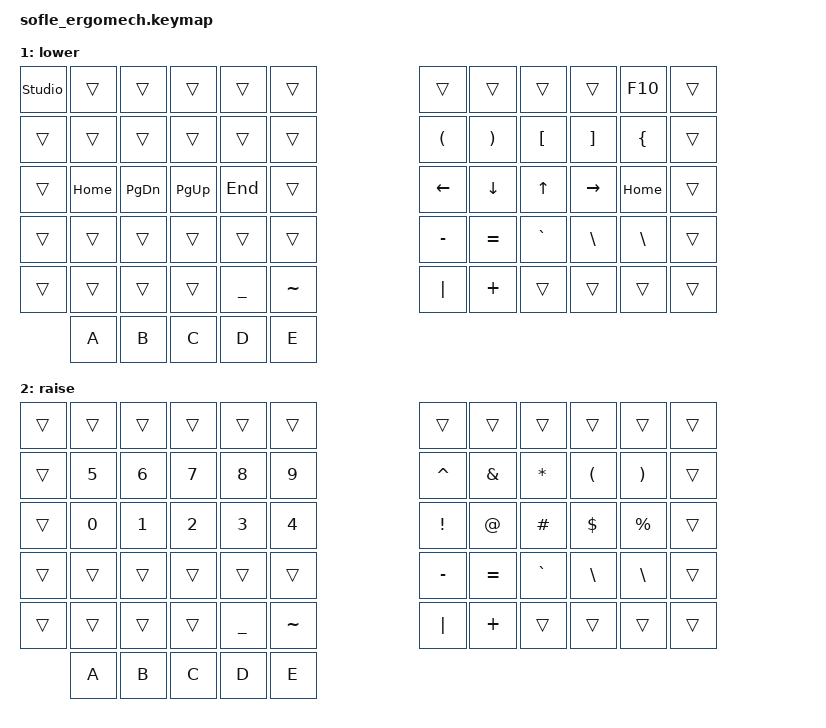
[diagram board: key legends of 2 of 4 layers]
/*
 * Copyright (c) 2020 The ZMK Contributors
 *
 * SPDX-License-Identifier: MIT
 */

#include <behaviors.dtsi>
#include <dt-bindings/zmk/bt.h>
#include <dt-bindings/zmk/ext_power.h>
#include <dt-bindings/zmk/keys.h>
#include <dt-bindings/zmk/rgb.h>

#define BASE 0
#define LOWER 1
#define RAISE 2
#define ADJUST 3

/ {
    behaviors {
        hml: home_row_mod_left {
            compatible = "zmk,behavior-hold-tap";
            #binding-cells = <2>;
            flavor = "tap-preferred";
            require-prior-idle-ms = <200>;
            tapping-term-ms = <175>;
            quick-tap-ms = <175>;
            bindings = <&kp>, <&kp>;
            hold-trigger-key-positions = <6 7 8 9 10 18 19 20 21 22 30 31 32 33 34 44 45 46 47 52 53>; // right hand
            hold-trigger-on-release;
        };
        hmr: home_row_mod_right {
            compatible = "zmk,behavior-hold-tap";
            #binding-cells = <2>;
            flavor = "tap-preferred";
            require-prior-idle-ms = <200>;
            tapping-term-ms = <280>;
            quick-tap-ms = <175>;
            bindings = <&kp>, <&kp>;
            hold-trigger-key-positions = <0 1 2 3 4 12 13 14 15 16 24 25 26 27 28 37 38 39 40 48 49>; // left hand
            hold-trigger-on-release;
        };
    };
    // Activate ADJUST layer by pressing raise and lower

    conditional_layers {
        compatible = "zmk,conditional-layers";

        adjust_layer {
            if-layers = <LOWER RAISE>;
            then-layer = <ADJUST>;
        };
    };

   key-positions {
       compatible = "zmk,key-positions";
       positions = <
            0  1  2  3  4  5     6  7  8  9 10 11
           12 13 14 15 16 17    18 19 20 21 22 23
           24 25 26 27 28 29    30 31 32 33 34 35
           36 37 38 39 40 41    42 43 44 45 46 47
                     48 49 50  51 52 53
       >;
   };

   keymap {
       compatible = "zmk,keymap";

       default_layer {
            label = "default";

            // ------------------------------------------------------------------------------------------------------------
            // |   `   |  1  |  2  |  3   |  4   |  5   |                   |  6   |  7    |  8    |  9   |   0   |       |
            // |  ESC  |  Q  |  W  |  E   |  R   |  T   |                   |  Y   |  U    |  I    |  O   |   P   | BKSPC |
            // |  TAB  |  A  |  S  |  D   |  F   |  G   |                   |  H   |  J    |  K    |  L   |   ;   |   '   |
            // | SHIFT |  Z  |  X  |  C   |  V   |  B   |  MUTE  |  |       |  N   |  M    |  ,    |  .   |   /   | SHIFT |
            //               | GUI | ALT  | CTRL | LOWER|  ENTER |  | SPACE | RAISE| CTRL  | ALT   | GUI  |

            bindings = <
&kp GRAVE   &kp N1       &kp N2        &kp N3       &kp N4        &kp N5                             &kp N6      &kp N7        &kp N8       &kp N9        &kp N0          &none
&kp ESC     &kp Q        &kp W         &kp E        &kp R         &kp T                              &kp Y       &kp U         &kp I        &kp O         &kp P           &kp BSPC
&kp TAB     &hml LALT A  &hml LSHFT S  &hml LGUI D  &hml LCTRL F  &kp G                              &kp H       &hmr RCTRL J  &hmr RGUI K  &hmr RSHFT L  &hmr RALT SEMI  &kp SQT
&kp LSHFT   &kp Z        &kp X         &kp C        &kp V         &kp B                              &kp N       &kp M         &kp COMMA    &kp DOT       &kp FSLH        &kp RSHFT
            &kp C_MUTE   &lt 2 LGUI    &lt 3 LALT   &lt 2 ESC     &lt 1 TAB  &kp SPACE    &kp ENTER  &lt 1 BSPC  &lt 2 DEL     &kp RALT     &kp RGUI 

            &kp ENTER  &kp RIGHT  &kp UP  &kp LEFT  &kp DOWN
        >;

            sensor-bindings = <&inc_dec_kp C_VOL_UP C_VOL_DN &inc_dec_kp PG_UP PG_DN>;
    };

        lower_layer {
            label = "lower";

            // TODO: Some binds are waiting for shifted keycode support.
            // ------------------------------------------------------------------------------------------------------------
            // |       |  F1 |  F2 |  F3  |  F4  |  F5  |                   |  F6  |  F7   |  F8   |  F9  |  F10  |  F11  |
            // |   `   |  1  |  2  |  3   |  4   |  5   |                   |  6   |  7    |  8    |  9   |   0   |  F12  |
            // |       |  !  |  @  |  #   |  $   |  %   |                   |  <-  |   v   |   ^   |  ->  |  HOME |  END  |
            // |       |  =  |  -  |  +   |  {   |  }   |        |  |       |  [   |  ]    |  ;    |  :   |   \   |       |
            //               |     |      |      |      |        |  |       |      |       |       |      |

            bindings = <
&studio_unlock  &trans     &trans     &trans     &trans    &trans                           &trans     &trans     &trans     &trans     &kp F10   &trans
&trans          &trans     &trans     &trans     &trans    &trans                           &kp LPAR   &kp RPAR   &kp LBKT   &kp RBKT   &kp LBRC  &trans
&trans          &kp HOME   &kp PG_DN  &kp PG_UP  &kp END   &trans                           &kp LEFT   &kp DOWN   &kp UP     &kp RIGHT  &kp HOME  &trans
&trans          &trans     &trans     &trans     &trans    &trans                           &kp MINUS  &kp EQUAL  &kp GRAVE  &kp BSLH   &kp BSLH  &trans
&trans                     &trans     &trans     &trans    &kp UNDER  &kp TILDE   &kp PIPE  &kp PLUS   &trans     &trans     &trans     &trans
                
                &kp A      &kp B     &kp C      &kp D      &kp E
        >;

            sensor-bindings = <&inc_dec_kp C_VOL_UP C_VOL_DN &inc_dec_kp PG_UP PG_DN>;
    };

        raise_layer {
            label = "raise";

            // ------------------------------------------------------------------------------------------------------------
            // | BTCLR | BT1  | BT2  |  BT3  |  BT4  |  BT5 |                |      |      |       |      |       |       |
            // |       |  5   |  6   |   7   |   8   |   9  |                |  ^   |  &   |  *    |  (   |   )   |   |   |
            // |       |  0   |  1   |   2   |   3   |   4  |                |  !   |  @   |  #    |  $   |  %    |       |
            // |       | UNDO | CUT  | COPY  | PASTE |      |      |  |      |      |      |       |      |       |       |
            //                |      |       |       |      |      |  |      |      |      |       |      |

            bindings = <
&trans  &trans  &trans  &trans  &trans  &trans                            &trans        &trans     &trans     &trans      &trans     &trans
&trans  &kp N5  &kp N6  &kp N7  &kp N8  &kp N9                            &kp CARET     &kp AMPS   &kp ASTRK  &kp LPAR    &kp RPAR   &trans
&trans  &kp N0  &kp N1  &kp N2  &kp N3  &kp N4                            &kp EXCL      &kp AT     &kp HASH   &kp DOLLAR  &kp PRCNT  &trans
&trans  &trans  &trans  &trans  &trans  &trans                            &kp MINUS     &kp EQUAL  &kp GRAVE  &kp BSLH    &kp BSLH   &trans
&trans          &trans  &trans  &trans  &kp UNDER  &kp TILDE    &kp PIPE  &kp PLUS      &trans     &trans     &trans      &trans
        &kp A      &kp B     &kp C     &kp D      &kp E
        >;

            sensor-bindings = <&inc_dec_kp C_VOL_UP C_VOL_DN &inc_dec_kp PG_UP PG_DN>;
        };

        adjust_layer {
            // ----------------------------------------------------------------------------------------------------------------------------
            // | BTCLR  |  BT1    |  BT2    |   BT3   |   BT4   |   BT5   |                  |      |      |       |      |       |       |
            // | EXTPWR | RGB_HUD | RGB_HUI | RGB_SAD | RGB_SAI | RGB_EFF |                  |      |      |       |      |       |       |
            // |        | RGB_BRD | RGB_BRI |         |         |         |                  |      |      |       |      |       |       |
            // |        |         |         |         |         |         | RGB_TOG | |      |      |      |       |      |       |       |
            //                    |         |         |         |         |         | |      |      |      |       |      |

            label = "adjust";
            bindings = <
&bt BT_CLR  &bt BT_SEL 0  &bt BT_SEL 1  &bt BT_SEL 2  &bt BT_SEL 3  &bt BT_SEL 4  &trans     &trans    &trans    &trans     &trans   &trans
&ext_power EP_TOG  &rgb_ug RGB_HUD  &rgb_ug RGB_HUI  &rgb_ug RGB_SAD  &rgb_ug RGB_SAI  &rgb_ug RGB_EFF  &none  &none  &none  &none  &none  &none
&none              &rgb_ug RGB_BRD  &rgb_ug RGB_BRI  &none            &none            &none            &none  &none  &none  &none  &none  &none
&none              &none            &none            &none            &none            &none            &none  &none  &none  &none  &none  &none
&rgb_ug RGB_TOG    &none            &none            &none            &none            &none            &none  &none  &none  &none  &none
                                                                                                        &kp A  &kp B  &kp C  &kp D  &kp E
            >;
        };
    };
};
